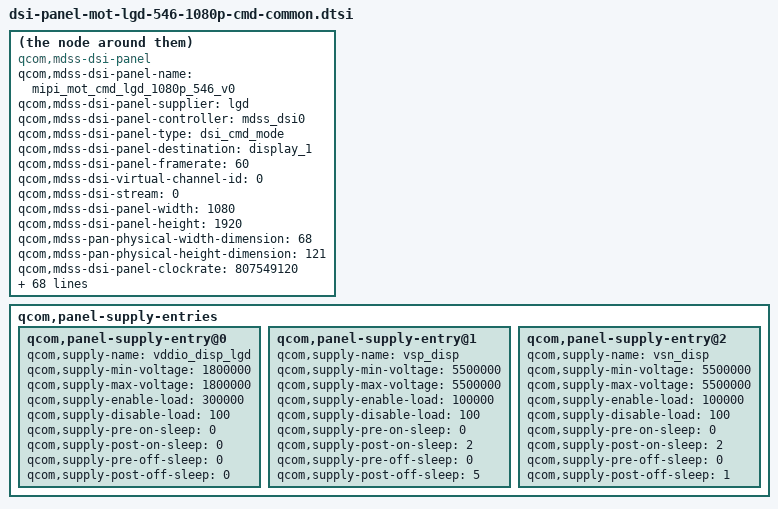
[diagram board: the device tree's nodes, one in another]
/* Copyright (c) 2015, The Linux Foundation. All rights reserved.
 *
 * This program is free software; you can redistribute it and/or modify
 * it under the terms of the GNU General Public License version 2 and
 * only version 2 as published by the Free Software Foundation.
 *
 * This program is distributed in the hope that it will be useful,
 * but WITHOUT ANY WARRANTY; without even the implied warranty of
 * MERCHANTABILITY or FITNESS FOR A PARTICULAR PURPOSE.  See the
 * GNU General Public License for more details.
 */

compatible = "qcom,mdss-dsi-panel";
qcom,mdss-dsi-panel-name = "mipi_mot_cmd_lgd_1080p_546_v0";
qcom,mdss-dsi-panel-supplier = "lgd";
qcom,mdss-dsi-panel-controller = <&mdss_dsi0>;
qcom,mdss-dsi-panel-type = "dsi_cmd_mode";
qcom,mdss-dsi-panel-destination = "display_1";
qcom,mdss-dsi-panel-framerate = <60>;
qcom,mdss-dsi-virtual-channel-id = <0>;
qcom,mdss-dsi-stream = <0>;
qcom,mdss-dsi-panel-width = <1080>;
qcom,mdss-dsi-panel-height = <1920>;
qcom,mdss-pan-physical-width-dimension = <68>;
qcom,mdss-pan-physical-height-dimension = <121>;

qcom,mdss-dsi-panel-clockrate = <807549120>;
qcom,mdss-dsi-h-front-porch = <24>;
qcom,mdss-dsi-h-back-porch = <40>;
qcom,mdss-dsi-h-pulse-width = <4>;
qcom,mdss-dsi-h-sync-skew = <0>;
qcom,mdss-dsi-v-back-porch = <16>;
qcom,mdss-dsi-v-front-porch = <16>;
qcom,mdss-dsi-v-pulse-width = <2>;
qcom,mdss-dsi-h-left-border = <0>;
qcom,mdss-dsi-h-right-border = <0>;
qcom,mdss-dsi-v-top-border = <0>;
qcom,mdss-dsi-v-bottom-border = <0>;
qcom,mdss-dsi-bpp = <24>;
qcom,mdss-dsi-underflow-color = <0xff>;
qcom,mdss-dsi-border-color = <0>;
qcom,mdss-dsi-on-command = [
	05 01 00 00 78 00 01 11
	23 01 00 00 00 00 02 B0 00       /* MCS Protect */
	29 01 00 00 00 00 02 FA 20       /* CABC RGB full PWM */
	/* CABC PWM setting */
	29 01 00 00 00 00 18 CE 5D 40 43 49 55 62 71 82 94 A8 B9 CB DB E9 FE FE FF 03 15 04 04 00 00
	/* CABC UI mode setting */
	29 01 00 00 00 00 07 B8 07 8B 19 08 0C 21
	/* CABC Moving Image mode setting */
	29 01 00 00 00 00 07 BA 07 7A 64 18 30 8D
	/* Set Max Brightness */
	15 01 00 00 00 00 02 51 BD
	/* Set Minimum Brightness */
	15 01 00 00 00 00 02 5E 00
	/* BLU control */
	15 01 00 00 00 00 02 53 2C
	/* set defaut CABC to UI mode */
	15 01 00 00 00 00 02 55 01
	05 01 00 00 00 00 01 29];	/* display on */
qcom,mdss-dsi-off-command = [
	05 01 00 00 0a 00 01 28		/* display_off */
	05 01 00 00 55 00 01 10];	/* enter sleep mode */
qcom,mdss-dsi-use-blank-in-progress-notifier;

/*Dynamic cabc*/
qcom,mdss-dsi-cabc-ui-command = [15 01 00 00 00 00 02 55 01];
qcom,mdss-dsi-cabc-mv-command = [15 01 00 00 00 00 02 55 03];
qcom,mdss-dsi-cabc-dis-command = [15 01 00 00 00 00 02 55 00];
qcom,mdss-dsi-hbm-on-command = [15 01 00 00 00 00 02 51 EB];
qcom,mdss-dsi-hbm-off-command = [15 01 00 00 00 00 02 51 BD];
qcom,mdss-dsi-hbm-type = "lcd-dcs-wled";


qcom,mdss-dsi-on-command-state = "dsi_lp_mode";
qcom,mdss-dsi-off-command-state = "dsi_lp_mode";
qcom,mdss-dsi-h-sync-pulse = <0>;
qcom,mdss-dsi-traffic-mode = "burst_mode";
qcom,mdss-dsi-bllp-eof-power-mode;
qcom,mdss-dsi-bllp-power-mode;
qcom,mdss-dsi-lane-0-state;
qcom,mdss-dsi-lane-1-state;
qcom,mdss-dsi-lane-2-state;
qcom,mdss-dsi-lane-3-state;
qcom,mdss-dsi-panel-timings = [d6 32 22 00 60 66 26 36 28 03 04 00];
qcom,mdss-dsi-t-clk-post = <0x1b>;
qcom,mdss-dsi-t-clk-pre = <0x28>;
qcom,mdss-dsi-bl-min-level = <1>;
qcom,mdss-dsi-bl-max-level = <255>;
qcom,mdss-dsi-bl-on-defer-delay = <60>;
qcom,mdss-dsi-dma-trigger = "trigger_sw";
qcom,mdss-dsi-mdp-trigger = "none";
qcom,mdss-dsi-bl-pmic-control-type = "bl_ctrl_wled";
qcom,mdss-dsi-reset-sequence = <1 11>;
qcom,mdss-dsi-dis-reset-sequence = <0 4>;
qcom,mdss-dsi-lp11-init;
qcom,mdss-dsi-tx-eot-append;

qcom,mdss-dsi-te-pin-select = <1>;
qcom,mdss-dsi-te-dcs-command = <1>;
qcom,mdss-dsi-te-check-enable;
qcom,mdss-dsi-te-using-te-pin;

qcom,esd-check-enabled;
qcom,mdss-dsi-panel-status-check-mode = "reg_read";
qcom,mdss-dsi-panel-status-command = [06 01 00 01 00 00 01 0A];
qcom,mdss-dsi-panel-status-command-state = "dsi_hs_mode";
qcom,mdss-dsi-panel-status-value = <0x1c>;

qcom,cont-splash-enabled;

qcom,panel-supply-entries {
	#address-cells = <1>;
	#size-cells = <0>;

	qcom,panel-supply-entry@0 {
		qcom,supply-name = "vddio_disp_lgd";
		qcom,supply-min-voltage = <1800000>;
		qcom,supply-max-voltage = <1800000>;
		qcom,supply-enable-load = <300000>;
		qcom,supply-disable-load = <100>;
		/* This is always on, no delays needed */
		qcom,supply-pre-on-sleep = <0>;
		qcom,supply-post-on-sleep = <0>;
		qcom,supply-pre-off-sleep = <0>;
		qcom,supply-post-off-sleep = <0>;
	};
        qcom,panel-supply-entry@1 {
		qcom,supply-name = "vsp_disp";
		qcom,supply-min-voltage = <5500000>;
		qcom,supply-max-voltage = <5500000>;
		qcom,supply-enable-load = <100000>;
		qcom,supply-disable-load = <100>;
		qcom,supply-pre-on-sleep = <0>;
		qcom,supply-post-on-sleep = <2>;
		qcom,supply-pre-off-sleep = <0>;
		qcom,supply-post-off-sleep = <5>;
	};
	qcom,panel-supply-entry@2 {
		qcom,supply-name = "vsn_disp";
		qcom,supply-min-voltage = <5500000>;
		qcom,supply-max-voltage = <5500000>;
		qcom,supply-enable-load = <100000>;
		qcom,supply-disable-load = <100>;
		qcom,supply-pre-on-sleep = <0>;
		qcom,supply-post-on-sleep = <2>;
		qcom,supply-pre-off-sleep = <0>;
		qcom,supply-post-off-sleep = <1>;
	};
};
